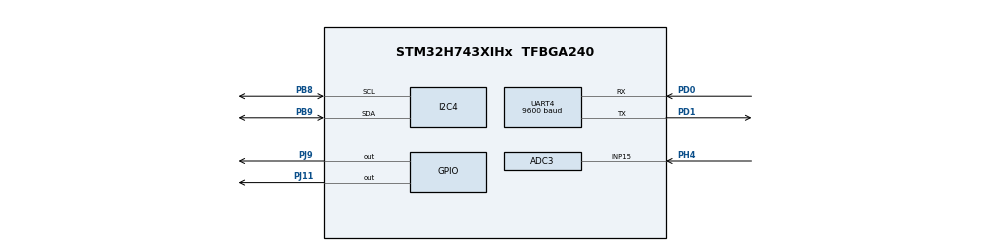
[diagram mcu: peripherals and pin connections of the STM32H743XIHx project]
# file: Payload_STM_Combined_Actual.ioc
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ADC3.Channel-0\#ChannelRegularConversion=ADC_CHANNEL_15
ADC3.NbrOfConversionFlag=1
ADC3.OffsetNumber-0\#ChannelRegularConversion=ADC_OFFSET_NONE
ADC3.OffsetSignedSaturation-0\#ChannelRegularConversion=DISABLE
ADC3.Rank-0\#ChannelRegularConversion=1
ADC3.SamplingTime-0\#ChannelRegularConversion=ADC_SAMPLETIME_1CYCLE_5
CORTEX_M7.default_mode_Activation=1
I2C4.Timing=0x00707CBB
Mcu.Family=STM32H7
Mcu.Name=STM32H743XIHx
Mcu.Package=TFBGA240
NVIC.PriorityGroup=NVIC_PRIORITYGROUP_4
PB8.Mode=I2C
PB8.Signal=I2C4_SCL
PB9.Mode=I2C
PB9.Signal=I2C4_SDA
PD0.Mode=Asynchronous
PD0.Signal=UART4_RX
PD1.Mode=Asynchronous
PD1.Signal=UART4_TX
PH4.Mode=IN15-Single-Ended
PH4.Signal=ADC3_INP15
PJ11.Signal=GPIO_Output
PJ9.Signal=GPIO_Output
ProjectManager.HeapSize=0x200
ProjectManager.StackSize=0x400
ProjectManager.TargetToolchain=STM32CubeIDE
RCC.ADCFreq_Value=80000000
RCC.APB1Freq_Value=32000000
RCC.APB2Freq_Value=64000000
RCC.APB3Freq_Value=64000000
RCC.APB4Freq_Value=32000000
RCC.CortexFreq_Value=64000000
RCC.D2PPRE1=RCC_APB1_DIV2
RCC.D3PPRE=RCC_APB4_DIV2
RCC.DIVM2=4
RCC.DIVN2=10
RCC.HCLKFreq_Value=64000000
RCC.PLL2FRACN=0
RCC.SYSCLKFreq_VALUE=64000000
RCC.USBFreq_Value=129000000
UART4.BaudRate=9600
VP_MEMORYMAP_VS_MEMORYMAP.Mode=CurAppReg
board=custom

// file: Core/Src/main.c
/* USER CODE BEGIN Header */
/**
  ******************************************************************************
  * @file           : main.c
  * @brief          : Main program body
  ******************************************************************************
  * @attention
  *
  * Copyright (c) 2026 STMicroelectronics.
  * All rights reserved.
  *
  * This software is licensed under terms that can be found in the LICENSE file
  * in the root directory of this software component.
  * If no LICENSE file comes with this software, it is provided AS-IS.
  *
  ******************************************************************************
  */
/* USER CODE END Header */
#include "main.h"

/* USER CODE BEGIN Includes */
#include "payload.h"
#include "langmuir.h"
#include "gps_task.h"
/* USER CODE END Includes */

/* USER CODE BEGIN PV */
ADC_HandleTypeDef hadc3;
I2C_HandleTypeDef hi2c4;
UART_HandleTypeDef huart4;

GOOSE_Payload payload_out = {0};  // <-- add this
/* USER CODE END PV */

void SystemClock_Config(void);
static void MPU_Config(void);
static void MX_GPIO_Init(void);
static void MX_ADC3_Init(void);
static void MX_I2C4_Init(void);
static void MX_UART4_Init(void);

int main(void)
{

  /* MPU Configuration--------------------------------------------------------*/
  MPU_Config();

  /* MCU Configuration--------------------------------------------------------*/

  /* Reset of all peripherals, Initializes the Flash interface and the Systick. */
  HAL_Init();

  /* Configure the system clock */
  SystemClock_Config();

  /* Initialize all configured peripherals */
  MX_GPIO_Init();
  MX_ADC3_Init();
  MX_I2C4_Init();
  MX_UART4_Init();
  /* USER CODE BEGIN 2 */

  // BURN WIRE TASK

  //  HAL_GPIO_WritePin(GPIOJ, GPIO_PIN_11, GPIO_PIN_SET);
//  HAL_Delay(2000);
//  HAL_GPIO_WritePin(GPIOJ, GPIO_PIN_11, GPIO_PIN_RESET);

  PayloadContext ctx = {0};
  PayloadMode mode = MODE_SCIENCE;

  if (mode == MODE_SCIENCE)
  {
      gps_task_init();
      langmuir_init();
  }

  /* USER CODE END 2 */

  /* Infinite loop */
  /* USER CODE BEGIN WHILE */
  while (1)
  {

	// payload_task(&ctx, mode, &hi2c4, &huart4){
	// if (MODE_SCIENCE){
		// langmuir_task(&hi2c4)
		// gps_task(&huart4)
	// }
	// if (MODE_DEPLOYMENT){
		// burn_task(

	  payload_task(&ctx, mode, &hi2c4, &huart4, &payload_out);  // <-- pass struct
	  HAL_Delay(100);

    /* USER CODE END WHILE */

  }
}

void SystemClock_Config(void)
{
  RCC_OscInitTypeDef RCC_OscInitStruct = {0};
  RCC_ClkInitTypeDef RCC_ClkInitStruct = {0};

  /** Supply configuration update enable
  */
  HAL_PWREx_ConfigSupply(PWR_LDO_SUPPLY);

  /** Configure the main internal regulator output voltage
  */
  __HAL_PWR_VOLTAGESCALING_CONFIG(PWR_REGULATOR_VOLTAGE_SCALE3);

  while(!__HAL_PWR_GET_FLAG(PWR_FLAG_VOSRDY)) {}

  /** Macro to configure the PLL clock source
  */
  __HAL_RCC_PLL_PLLSOURCE_CONFIG(RCC_PLLSOURCE_HSI);

  /** Initializes the RCC Oscillators according to the specified parameters
  * in the RCC_OscInitTypeDef structure.
  */
  RCC_OscInitStruct.OscillatorType = RCC_OSCILLATORTYPE_HSI;
  RCC_OscInitStruct.HSIState = RCC_HSI_DIV1;
  RCC_OscInitStruct.HSICalibrationValue = RCC_HSICALIBRATION_DEFAULT;
  RCC_OscInitStruct.PLL.PLLState = RCC_PLL_NONE;
  if (HAL_RCC_OscConfig(&RCC_OscInitStruct) != HAL_OK)
  {
    Error_Handler();
  }

  /** Initializes the CPU, AHB and APB buses clocks
  */
  RCC_ClkInitStruct.ClockType = RCC_CLOCKTYPE_HCLK|RCC_CLOCKTYPE_SYSCLK
                              |RCC_CLOCKTYPE_PCLK1|RCC_CLOCKTYPE_PCLK2
                              |RCC_CLOCKTYPE_D3PCLK1|RCC_CLOCKTYPE_D1PCLK1;
  RCC_ClkInitStruct.SYSCLKSource = RCC_SYSCLKSOURCE_HSI;
  RCC_ClkInitStruct.SYSCLKDivider = RCC_SYSCLK_DIV1;
  RCC_ClkInitStruct.AHBCLKDivider = RCC_HCLK_DIV1;
  RCC_ClkInitStruct.APB3CLKDivider = RCC_APB3_DIV1;
  RCC_ClkInitStruct.APB1CLKDivider = RCC_APB1_DIV2;
  RCC_ClkInitStruct.APB2CLKDivider = RCC_APB2_DIV1;
  RCC_ClkInitStruct.APB4CLKDivider = RCC_APB4_DIV2;

  if (HAL_RCC_ClockConfig(&RCC_ClkInitStruct, FLASH_LATENCY_1) != HAL_OK)
  {
    Error_Handler();
  }
}

static void MX_ADC3_Init(void)
{

  ADC_ChannelConfTypeDef sConfig = {0};

  /** Common config
  */
  hadc3.Instance = ADC3;
  hadc3.Init.Resolution = ADC_RESOLUTION_16B;
  hadc3.Init.ScanConvMode = ADC_SCAN_DISABLE;
  hadc3.Init.EOCSelection = ADC_EOC_SINGLE_CONV;
  hadc3.Init.LowPowerAutoWait = DISABLE;
  hadc3.Init.ContinuousConvMode = DISABLE;
  hadc3.Init.NbrOfConversion = 1;
  hadc3.Init.DiscontinuousConvMode = DISABLE;
  hadc3.Init.ExternalTrigConv = ADC_SOFTWARE_START;
  hadc3.Init.ExternalTrigConvEdge = ADC_EXTERNALTRIGCONVEDGE_NONE;
  hadc3.Init.ConversionDataManagement = ADC_CONVERSIONDATA_DR;
  hadc3.Init.Overrun = ADC_OVR_DATA_PRESERVED;
  hadc3.Init.LeftBitShift = ADC_LEFTBITSHIFT_NONE;
  hadc3.Init.OversamplingMode = DISABLE;
  hadc3.Init.Oversampling.Ratio = 1;
  if (HAL_ADC_Init(&hadc3) != HAL_OK)
  {
    Error_Handler();
  }

  /** Configure Regular Channel
  */
  sConfig.Channel = ADC_CHANNEL_15;
  sConfig.Rank = ADC_REGULAR_RANK_1;
  sConfig.SamplingTime = ADC_SAMPLETIME_1CYCLE_5;
  sConfig.SingleDiff = ADC_SINGLE_ENDED;
  sConfig.OffsetNumber = ADC_OFFSET_NONE;
  sConfig.Offset = 0;
  sConfig.OffsetSignedSaturation = DISABLE;
  if (HAL_ADC_ConfigChannel(&hadc3, &sConfig) != HAL_OK)
  {
    Error_Handler();
  }

}

static void MX_I2C4_Init(void)
{

  hi2c4.Instance = I2C4;
  hi2c4.Init.Timing = 0x00707CBB;
  hi2c4.Init.OwnAddress1 = 0;
  hi2c4.Init.AddressingMode = I2C_ADDRESSINGMODE_7BIT;
  hi2c4.Init.DualAddressMode = I2C_DUALADDRESS_DISABLE;
  hi2c4.Init.OwnAddress2 = 0;
  hi2c4.Init.OwnAddress2Masks = I2C_OA2_NOMASK;
  hi2c4.Init.GeneralCallMode = I2C_GENERALCALL_DISABLE;
  hi2c4.Init.NoStretchMode = I2C_NOSTRETCH_DISABLE;
  if (HAL_I2C_Init(&hi2c4) != HAL_OK)
  {
    Error_Handler();
  }

  /** Configure Analogue filter
  */
  if (HAL_I2CEx_ConfigAnalogFilter(&hi2c4, I2C_ANALOGFILTER_ENABLE) != HAL_OK)
  {
    Error_Handler();
  }

  /** Configure Digital filter
  */
  if (HAL_I2CEx_ConfigDigitalFilter(&hi2c4, 0) != HAL_OK)
  {
    Error_Handler();
  }

}

static void MX_UART4_Init(void)
{

  huart4.Instance = UART4;
  huart4.Init.BaudRate = 9600;
  huart4.Init.WordLength = UART_WORDLENGTH_8B;
  huart4.Init.StopBits = UART_STOPBITS_1;
  huart4.Init.Parity = UART_PARITY_NONE;
  huart4.Init.Mode = UART_MODE_TX_RX;
  huart4.Init.HwFlowCtl = UART_HWCONTROL_NONE;
  huart4.Init.OverSampling = UART_OVERSAMPLING_16;
  huart4.Init.OneBitSampling = UART_ONE_BIT_SAMPLE_DISABLE;
  huart4.Init.ClockPrescaler = UART_PRESCALER_DIV1;
  huart4.AdvancedInit.AdvFeatureInit = UART_ADVFEATURE_NO_INIT;
  if (HAL_UART_Init(&huart4) != HAL_OK)
  {
    Error_Handler();
  }
  if (HAL_UARTEx_SetTxFifoThreshold(&huart4, UART_TXFIFO_THRESHOLD_1_8) != HAL_OK)
  {
    Error_Handler();
  }
  if (HAL_UARTEx_SetRxFifoThreshold(&huart4, UART_RXFIFO_THRESHOLD_1_8) != HAL_OK)
  {
    Error_Handler();
  }
  if (HAL_UARTEx_DisableFifoMode(&huart4) != HAL_OK)
  {
    Error_Handler();
  }

}

static void MX_GPIO_Init(void)
{
  GPIO_InitTypeDef GPIO_InitStruct = {0};

  /* GPIO Ports Clock Enable */
  __HAL_RCC_GPIOB_CLK_ENABLE();
  __HAL_RCC_GPIOD_CLK_ENABLE();
  __HAL_RCC_GPIOJ_CLK_ENABLE();
  __HAL_RCC_GPIOH_CLK_ENABLE();

  /*Configure GPIO pin Output Level */
  HAL_GPIO_WritePin(GPIOJ, GPIO_PIN_11|GPIO_PIN_9, GPIO_PIN_RESET);

  /*Configure GPIO pins : PJ11 PJ9 */
  GPIO_InitStruct.Pin = GPIO_PIN_11|GPIO_PIN_9;
  GPIO_InitStruct.Mode = GPIO_MODE_OUTPUT_PP;
  GPIO_InitStruct.Pull = GPIO_NOPULL;
  GPIO_InitStruct.Speed = GPIO_SPEED_FREQ_LOW;
  HAL_GPIO_Init(GPIOJ, &GPIO_InitStruct);

}

 /* MPU Configuration */

void MPU_Config(void)
{
  MPU_Region_InitTypeDef MPU_InitStruct = {0};

  /* Disables the MPU */
  HAL_MPU_Disable();

  /** Initializes and configures the Region and the memory to be protected
  */
  MPU_InitStruct.Enable = MPU_REGION_ENABLE;
  MPU_InitStruct.Number = MPU_REGION_NUMBER0;
  MPU_InitStruct.BaseAddress = 0x0;
  MPU_InitStruct.Size = MPU_REGION_SIZE_4GB;
  MPU_InitStruct.SubRegionDisable = 0x87;
  MPU_InitStruct.TypeExtField = MPU_TEX_LEVEL0;
  MPU_InitStruct.AccessPermission = MPU_REGION_NO_ACCESS;
  MPU_InitStruct.DisableExec = MPU_INSTRUCTION_ACCESS_DISABLE;
  MPU_InitStruct.IsShareable = MPU_ACCESS_SHAREABLE;
  MPU_InitStruct.IsCacheable = MPU_ACCESS_NOT_CACHEABLE;
  MPU_InitStruct.IsBufferable = MPU_ACCESS_NOT_BUFFERABLE;

  HAL_MPU_ConfigRegion(&MPU_InitStruct);
  /* Enables the MPU */
  HAL_MPU_Enable(MPU_PRIVILEGED_DEFAULT);

}

void Error_Handler(void)
{
  __disable_irq();
  while (1)
  {
  }
}
